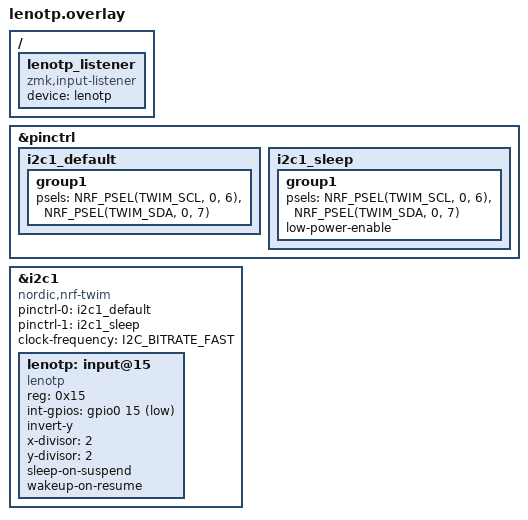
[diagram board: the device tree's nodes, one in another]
#include <dt-bindings/gpio/gpio.h>
#include <dt-bindings/i2c/i2c.h>
#include <dt-bindings/pinctrl/nrf-pinctrl.h>

&pinctrl {
    i2c1_default: i2c1_default {
        group1 {
            psels = <NRF_PSEL(TWIM_SCL, 0, 6)>,
                    <NRF_PSEL(TWIM_SDA, 0, 7)>;
        };
    };

    i2c1_sleep: i2c1_sleep {
        group1 {
            psels = <NRF_PSEL(TWIM_SCL, 0, 6)>,
                    <NRF_PSEL(TWIM_SDA, 0, 7)>;
            low-power-enable;
        };
    };
};

&i2c1 {
    compatible = "nordic,nrf-twim";
    status = "okay";
    pinctrl-0 = <&i2c1_default>;
    pinctrl-1 = <&i2c1_sleep>;
    pinctrl-names = "default", "sleep";
    clock-frequency = <I2C_BITRATE_FAST>;

    lenotp: input@15 {
        compatible = "lenotp";
        reg = <0x15>;
        status = "okay";
        int-gpios = <&gpio0 15 (GPIO_ACTIVE_LOW | GPIO_PULL_UP)>;

        /* Optional tuning */
        invert-y;
        x-divisor = <2>;
        y-divisor = <2>;

        /* Wireless-friendly suspend/resume */
        sleep-on-suspend;
        wakeup-on-resume;

        /*
         * If your PCB can switch the lenoTP supply with a load switch,
         * wire its enable pin here and uncomment power-off-on-suspend.
         */
        /* power-gpios = <&gpio0 14 GPIO_ACTIVE_HIGH>; */
        /* power-off-on-suspend; */
    };
};

/ {
    lenotp_listener: lenotp_listener {
        compatible = "zmk,input-listener";
        device = <&lenotp>;
    };
};
